AUTOSAR XML (schema 4-0-3)
standard types defined: Boolean, UInt32
package /AUTOSAR_Platform/DataConstrs
  range DC_Boolean: raw 0..1
package /PATAC/MSM/ComponentTypes
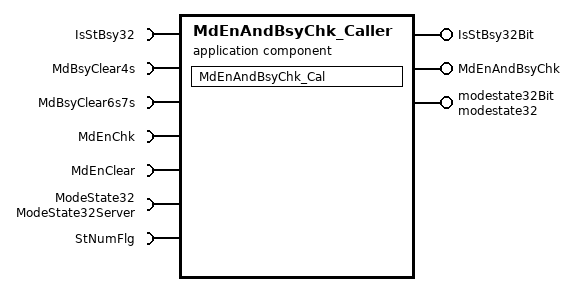
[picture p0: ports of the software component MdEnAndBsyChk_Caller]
  application sw component type MdEnAndBsyChk_Caller
    provide port IsStBsy32Bit: nonqueued-sender-com-spec{data-element=IsStBsy32Bit/Val, init-value=0}, provided-interface=IsStBsy32Bit
    provide port MdEnAndBsyChk: server-com-spec{operation=MdEnAndBsyChk/Cal, queue-length=1}, provided-interface=MdEnAndBsyChk
    provide port modestate32Bit: nonqueued-sender-com-spec{data-element=modestate32/Val, init-value=0}, provided-interface=modestate32
    7 x require port:
      IsStBsy32: required-com-specs=[IsStBsy32/Clear, IsStBsy32/Get, IsStBsy32/Set], required-interface=IsStBsy32
      MdBsyClear4s: client-com-spec=MdBsyClear4s/Cal, required-interface=MdBsyClear4s
      MdBsyClear6s7s: client-com-spec=MdBsyClear6s7s/Cal, required-interface=MdBsyClear6s7s
      MdEnChk: client-com-spec=MdEnChk/Cal, required-interface=MdEnChk
      MdEnClear: client-com-spec=MdEnClear/Cal, required-interface=MdEnClear
      ModeState32: required-com-specs=[ModeState32Server/Clear, ModeState32Server/Get, ModeState32Server/Set], required-interface=ModeState32Server
      StNumFlg: required-interface=StNumFlg
        required-com-specs:
          data-element=Is4s, filter=data-filter-type=ALWAYS, init-value=0
          data-element=Is6s, filter=data-filter-type=ALWAYS, init-value=0
          data-element=Is6s7s, filter=data-filter-type=ALWAYS, init-value=0
          data-element=Is7s, filter=data-filter-type=ALWAYS, init-value=0
    behavior MdEnAndBsyChk_Caller_InternalBehavior
      operation invoked event OIT_MdEnAndBsyChk_Cal_MdEnAndBsyChk_Cal: start-on-event=MdEnAndBsyChk_Cal, operation=MdEnAndBsyChk.Cal
      runnable MdEnAndBsyChk_Cal
        data-receive-point-by-arguments:
          4 x access:
            REC_StNumFlg_Is4s: accessed-variable=StNumFlg.Is4s
            REC_StNumFlg_Is6s: accessed-variable=StNumFlg.Is6s
            REC_StNumFlg_Is6s7s: accessed-variable=StNumFlg.Is6s7s
            REC_StNumFlg_Is7s: accessed-variable=StNumFlg.Is7s
        data-send-points:
          access SEND_IsStBsy32Bit_Val: accessed-variable=IsStBsy32Bit.Val
          access SEND_modestate32_Val: accessed-variable=modestate32Bit.Val
        6 x sync call, all with timeout=0:
          SC_IsStBsy32_Get: operation=IsStBsy32.Get
          SC_MdBsyClear4s_Cal: operation=MdBsyClear4s.Cal
          SC_MdBsyClear6s7s_Cal: operation=MdBsyClear6s7s.Cal
          SC_MdEnChk_Cal: operation=MdEnChk.Cal
          SC_MdEnClear_Cal: operation=MdEnClear.Cal
          SC_ModeState32_Get: operation=ModeState32.Get
  swc implementation MdEnAndBsyChk_Caller_Implementation: behavior=MdEnAndBsyChk_Caller_InternalBehavior
    code-descriptors:
      code Default: artifact-descriptors=autosar-engineering-object={short-label=Default, category=SWSRC}
package /PATAC/MSM/ModeAdjust/PortInterface
  7 x client server interface:
    IsStBsy32
      operation Clear
        arg ClearBit: type=UInt32, direction=IN, server-argument-impl-policy=USE-ARGUMENT-TYPE
      operation Get
        arg IsStBsy32Bit: type=UInt32, direction=OUT, server-argument-impl-policy=USE-ARGUMENT-TYPE
      operation Set
        arg SetBit: type=UInt32, direction=IN, server-argument-impl-policy=USE-ARGUMENT-TYPE
    MdBsyClear4s
      operation Cal
    MdBsyClear6s7s
      operation Cal
    MdEnAndBsyChk
      operation Cal
        arg modestate32: type=UInt32, direction=OUT, server-argument-impl-policy=USE-ARGUMENT-TYPE
    MdEnChk
      operation Cal  # StNun: 0 :4s 1:6s 2:7s 3:4sp
    MdEnClear
      operation Cal
    ModeState32Server
      operation Clear
        arg ClearBit: type=UInt32, direction=IN, server-argument-impl-policy=USE-ARGUMENT-TYPE
      operation Get
        arg MdEn32: type=UInt32, direction=OUT, server-argument-impl-policy=USE-ARGUMENT-TYPE
      operation Set
        arg SetBit: type=UInt32, direction=IN, server-argument-impl-policy=USE-ARGUMENT-TYPE
  sender receiver interface IsStBsy32Bit: invalidation-policy{data-element=IsStBsy32Bit/Val, handle-invalid=DONT-INVALIDATE}
    data Val: type=UInt32
  sender receiver interface modestate32: invalidation-policy{data-element=modestate32/Val, handle-invalid=DONT-INVALIDATE}
    data Val: type=UInt32
  sender receiver interface StNumFlg
    4 x data, all with type=Boolean:
      Is4s
      Is6s
      Is6s7s
      Is7s
    invalidation-policys:
      data-element=Is7s, handle-invalid=DONT-INVALIDATE
      data-element=Is6s, handle-invalid=DONT-INVALIDATE
      data-element=Is4s, handle-invalid=DONT-INVALIDATE
      data-element=Is6s7s, handle-invalid=DONT-INVALIDATE
